AUTOSAR XML (schema 4-3-0)
package /ApplicationLayer/Interface
  impl type IntImpl: category=VALUE, base-type=uint8
  app type Int: category=VALUE
  impl type SwitchStatusImpl: category=VALUE, base-type=uint8
  app type SwitchStatus: category=VALUE
  impl type MotorInterfaceImpl: category=VALUE, base-type=uint8
  app type MotorInterface: category=VALUE
  data type mapping set TypeMappings
    data-type-maps:
      application-data-type=Int, implementation-data-type=IntImpl
      application-data-type=SwitchStatus, implementation-data-type=SwitchStatusImpl
      application-data-type=MotorInterface, implementation-data-type=MotorInterfaceImpl
  4 x sender receiver interface:
    DataInterface
      data message: type=Int
    swtInterface
      data status: type=SwitchStatus
    mInterface
      data status: type=MotorInterface
    sensorStatusInterface
      data value: type=Int
package /ApplicationLayer/ApplicationPackage
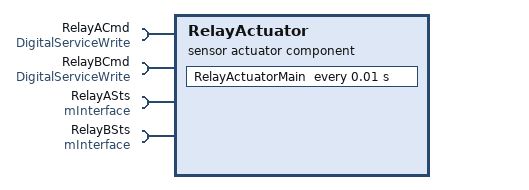
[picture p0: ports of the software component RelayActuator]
  sensor actuator sw component type RelayActuator
    4 x require port:
      RelayACmd: required-interface=DigitalServiceWrite
      RelayBCmd: required-interface=DigitalServiceWrite
      RelayASts: required-interface=mInterface
      RelayBSts: required-interface=mInterface
    behavior RelayActuatorBehavior: data-type-mapping=TypeMappings, handle-termination-and-restart=NO-SUPPORT
      timing event RelayActuatorMainEvent: start-on-event=RelayActuatorMain, period=0.01
      runnable RelayActuatorMain
        data-read-access:
          access dataReadAccess_RelayActuatorMain_RelayASts_status: accessed-variable=RelayASts.status
          access dataReadAccess_RelayActuatorMain_RelayBSts_status: accessed-variable=RelayBSts.status
        sync call RelayACmd_Write: operation=RelayACmd.Write, timeout=0.0
        sync call RelayBCmd_Write: operation=RelayBCmd.Write, timeout=0.0
  swc implementation RelayActuatorImpl: programming-language=C, vendor-id=0, behavior=RelayActuatorBehavior
    code-descriptors:
      code src: artifact-descriptors=autosar-engineering-object={short-label=artifactDescriptor, category=artifactDescriptorCategory}
    resource consumption resourceConsumption
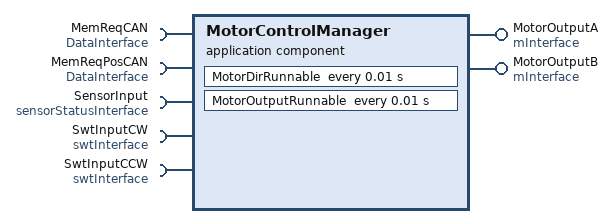
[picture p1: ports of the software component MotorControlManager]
  application sw component type MotorControlManager
    5 x require port:
      MemReqCAN: required-interface=DataInterface
      MemReqPosCAN: required-interface=DataInterface
      SensorInput: required-interface=sensorStatusInterface
      SwtInputCW: required-interface=swtInterface
      SwtInputCCW: required-interface=swtInterface
    provide port MotorOutputA: provided-interface=mInterface
    provide port MotorOutputB: provided-interface=mInterface
    behavior MotorControlManagerBehaviour: data-type-mapping=TypeMappings, handle-termination-and-restart=NO-SUPPORT
      timing event MotorDirRunnableEvent: start-on-event=MotorDirRunnable, period=0.01
      timing event MotorOutputRunnableEvent: start-on-event=MotorOutputRunnable, period=0.01
      runnable MotorDirRunnable: symbol=MotorDirRunnableMain
        data-read-access:
          5 x access:
            dataReadAccess_MotorDirRunnable_SwtInputCW_status: accessed-variable=SwtInputCW.status
            dataReadAccess_MotorDirRunnable_SwtInputCCW_status: accessed-variable=SwtInputCCW.status
            dataReadAccess_MotorDirRunnable_SensorInput_value: accessed-variable=SensorInput.value
            dataReadAccess_MotorDirRunnable_MemReqCAN_message: accessed-variable=MemReqCAN.message
            dataReadAccess_MotorDirRunnable_MemReqPosCAN_message: accessed-variable=MemReqPosCAN.message
      runnable MotorOutputRunnable: symbol=MotorOutputRunnableMain
        data-write-access:
          access dataWriteAccess_MotorOutputRunnable_MotorOutputA_status: accessed-variable=MotorOutputA.status
          access dataWriteAccess_MotorOutputRunnable_MotorOutputB_status: accessed-variable=MotorOutputB.status
  swc implementation MotorControlManagerImpl: programming-language=C, vendor-id=0, behavior=MotorControlManagerBehaviour
    code-descriptors:
      code src: artifact-descriptors=autosar-engineering-object={short-label=artifactDescriptor, category=artifactDescriptorCategory}
    resource consumption resourceConsumption
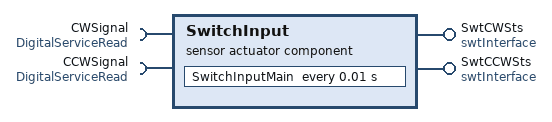
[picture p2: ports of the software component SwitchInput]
  sensor actuator sw component type SwitchInput
    require port CWSignal: required-interface=DigitalServiceRead
    require port CCWSignal: required-interface=DigitalServiceRead
    provide port SwtCWSts: provided-interface=swtInterface
    provide port SwtCCWSts: provided-interface=swtInterface
    behavior SwitchInputBehavior: data-type-mapping=TypeMappings, handle-termination-and-restart=NO-SUPPORT
      timing event SwitchInputMainEvent: start-on-event=SwitchInputMain, period=0.01
      runnable SwitchInputMain
        data-write-access:
          access dataWriteAccess_SwitchInputMain_SwtCWSts_status: accessed-variable=SwtCWSts.status
          access dataWriteAccess_SwitchInputMain_SwtCCWSts_status: accessed-variable=SwtCCWSts.status
        sync call CWSignal_Read: operation=CWSignal.Read, timeout=0.0
        sync call CCWSignal_Read: operation=CCWSignal.Read, timeout=0.0
  swc implementation SwitchInputImpl: programming-language=C, vendor-id=0, behavior=SwitchInputBehavior
    code-descriptors:
      code src: artifact-descriptors=autosar-engineering-object={short-label=artifactDescriptor, category=artifactDescriptorCategory}
    resource consumption resourceConsumption
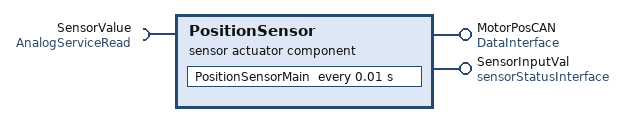
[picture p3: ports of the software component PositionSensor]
  sensor actuator sw component type PositionSensor
    require port SensorValue: required-interface=AnalogServiceRead
    provide port MotorPosCAN: provided-interface=DataInterface
    provide port SensorInputVal: provided-interface=sensorStatusInterface
    behavior PositionSensorBehavior: data-type-mapping=TypeMappings, handle-termination-and-restart=NO-SUPPORT
      timing event PositionSensorMainEvent: start-on-event=PositionSensorMain, period=0.01
      runnable PositionSensorMain
        data-write-access:
          access dataWriteAccess_PositionSensorMain_MotorPosCAN_message: accessed-variable=MotorPosCAN.message
          access dataWriteAccess_PositionSensorMain_SensorInputVal_value: accessed-variable=SensorInputVal.value
        sync call SensorValue_Read: operation=SensorValue.Read, timeout=0.0
  swc implementation PositionSensorImpl: programming-language=C, vendor-id=0, behavior=PositionSensorBehavior
    code-descriptors:
      code src: artifact-descriptors=autosar-engineering-object={short-label=artifactDescriptor, category=artifactDescriptorCategory}
    resource consumption resourceConsumption
package /ApplicationLayer/CompositionPackage
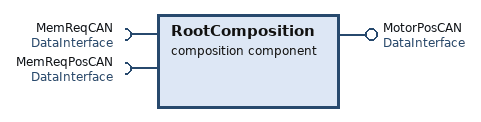
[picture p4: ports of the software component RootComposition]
  composition sw component type RootComposition
    require port MemReqCAN: required-interface=DataInterface
    require port MemReqPosCAN: required-interface=DataInterface
    provide port MotorPosCAN: provided-interface=DataInterface
    5 x component:
      PositionSensorInstance: type=PositionSensor
      SwitchInputInstance: type=SwitchInput
      RelayActuatorInstance: type=RelayActuator
      MotorControlManagerInstance: type=MotorControlManager
      IoHwAbInstance: type=IoHwAb
    connect SwitchInputInstance.SwtCWSts -> MotorControlManagerInstance.SwtInputCW
    connect SwitchInputInstance.SwtCCWSts -> MotorControlManagerInstance.SwtInputCCW
    connect MotorControlManagerInstance.MotorOutputA -> RelayActuatorInstance.RelayASts
    connect MotorControlManagerInstance.MotorOutputB -> RelayActuatorInstance.RelayBSts
    connect PositionSensorInstance.SensorInputVal -> MotorControlManagerInstance.SensorInput
    connect IoHwAbInstance.Digital_SwtCW -> SwitchInputInstance.CWSignal
    connect IoHwAbInstance.Digital_SwtCCW -> SwitchInputInstance.CCWSignal
    connect IoHwAbInstance.Digital_RelayA -> RelayActuatorInstance.RelayACmd
    connect IoHwAbInstance.Digital_RelayB -> RelayActuatorInstance.RelayBCmd
    connect IoHwAbInstance.Analog_Sensor -> PositionSensorInstance.SensorValue
    delegate MotorControlManagerInstance.MemReqCAN <-> outer port RootComposition/MemReqCAN
    delegate MotorControlManagerInstance.MemReqPosCAN <-> outer port RootComposition/MemReqPosCAN
    delegate PositionSensorInstance.MotorPosCAN <-> outer port RootComposition/MotorPosCAN
package /ApplicationLayer/Signals
  pdu ECU1_01_3FE: unused-bit-pattern=0
    signal ISignalSEAT_MEM_REQ_POS: 0 bit, data-type-policy=NETWORK-REPRESENTATION-FROM-COM-SPEC
    signal ISignalSEAT_MEM_Req: 0 bit, data-type-policy=NETWORK-REPRESENTATION-FROM-COM-SPEC
  pdu ECU2_01_3FF: unused-bit-pattern=0
    signal ISignalSEAT_POS: 0 bit, data-type-policy=NETWORK-REPRESENTATION-FROM-COM-SPEC
  pdu ECU01_01_3FE: unused-bit-pattern=0
    signal ISignalIntReq: 0 bit, data-type-policy=NETWORK-REPRESENTATION-FROM-COM-SPEC
  pdu MyECU_01_3FF: unused-bit-pattern=0
    signal ISignalLEDSts: 0 bit, data-type-policy=NETWORK-REPRESENTATION-FROM-COM-SPEC
    signal ISignalPotValue: 0 bit, data-type-policy=NETWORK-REPRESENTATION-FROM-COM-SPEC
package /ApplicationLayer/EcuExtract
  system MyAUTOSAREcuExtract: category=ECU_EXTRACT, system-version=1.0.0
    system mapping ImplementationMappings
      sw-impl-mappings:
        5 x swc to impl mapping:
          SwcToImplMapping_for_PositionSensorImpl_to_PositionSensorInstance: component-implementation=PositionSensorImpl, component=RootSwComposition.PositionSensorInstance
          SwcToImplMapping_for_SwitchInputImpl_to_SwitchInputInstance: component-implementation=SwitchInputImpl, component=RootSwComposition.SwitchInputInstance
          SwcToImplMapping_for_RelayActuatorImpl_to_RelayActuatorInstance: component-implementation=RelayActuatorImpl, component=RootSwComposition.RelayActuatorInstance
          SwcToImplMapping_for_MotorControlManagerImpl_to_MotorControlManagerInstance: component-implementation=MotorControlManagerImpl, component=RootSwComposition.MotorControlManagerInstance
          SwcToImplMapping_for_IoHwAbImpl_to_IoHwAbInstance: component-implementation=IoHwAbImpl, component=RootSwComposition.IoHwAbInstance
    system mapping SignalMappings
      data-mappings:
        data-element=RootSwComposition.MemReqCAN.message, system-signal=SEAT_MEM_Req
        data-element=RootSwComposition.MemReqPosCAN.message, system-signal=SEAT_MEM_REQ_POS
        data-element=RootSwComposition.MotorPosCAN.message, system-signal=SEAT_POS
    root-software-compositions:
      root sw composition prototype RootSwComposition: software-composition=RootComposition
package /BSWConfiguration/Services/IoHwAb
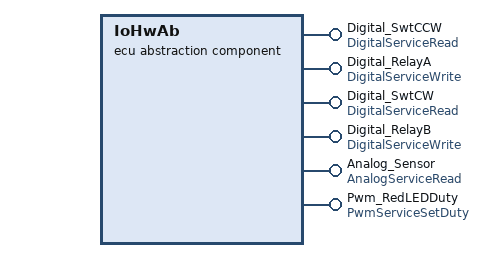
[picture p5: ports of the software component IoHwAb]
  ecu abstraction sw component type IoHwAb
    6 x provide port:
      Digital_SwtCCW: provided-interface=DigitalServiceRead
      Digital_RelayA: provided-interface=DigitalServiceWrite
      Digital_SwtCW: provided-interface=DigitalServiceRead
      Digital_RelayB: provided-interface=DigitalServiceWrite
      Analog_Sensor: provided-interface=AnalogServiceRead
      Pwm_RedLEDDuty: provided-interface=PwmServiceSetDuty
    behavior IoHwAbBehavior: handle-termination-and-restart=NO-SUPPORT
      6 x operation invoked event:
        DigitalRead_Digital_SwtCCW_Read: start-on-event=DigitalRead, operation=Digital_SwtCCW.Read
        DigitalRead_Digital_SwtCW_Read: start-on-event=DigitalRead, operation=Digital_SwtCW.Read
        DigitalWrite_Digital_RelayA_Write: start-on-event=DigitalWrite, operation=Digital_RelayA.Write
        DigitalWrite_Digital_RelayB_Write: start-on-event=DigitalWrite, operation=Digital_RelayB.Write
        AnalogRead_Analog_Sensor_Read: start-on-event=AnalogRead, operation=Analog_Sensor.Read
        PwmSetDuty_Pwm_RedLEDDuty_Set: start-on-event=PwmSetDuty, operation=Pwm_RedLEDDuty.Set
      port-api-options:
        {port-defined-argument-value{value=IoHwAb_SignalType_:0, value-type=IoHwAb_SignalType_}, port=Digital_SwtCCW}
        {port-defined-argument-value{value=IoHwAb_SignalType_:1, value-type=IoHwAb_SignalType_}, port=Digital_RelayA}
        {port-defined-argument-value{value=IoHwAb_SignalType_:2, value-type=IoHwAb_SignalType_}, port=Digital_SwtCW}
        {port-defined-argument-value{value=IoHwAb_SignalType_:3, value-type=IoHwAb_SignalType_}, port=Digital_RelayB}
        {port-defined-argument-value{value=IoHwAb_SignalType_:0, value-type=IoHwAb_SignalType_}, port=Analog_Sensor}
        {port-defined-argument-value{value=IoHwAb_SignalType_:0, value-type=IoHwAb_SignalType_}, port=Pwm_RedLEDDuty}
      4 x runnable, all with can-be-invoked-concurrently=true:
        DigitalRead: symbol=IoHwAb_Digital_Read
        DigitalWrite: symbol=IoHwAb_Digital_Write
        AnalogRead: symbol=IoHwAb_Analog_Read
        PwmSetDuty: symbol=IoHwAb_Pwm_Set_Duty
  swc implementation IoHwAbImpl: programming-language=C, vendor-id=60, behavior=IoHwAbBehavior
    code-descriptors:
      code src: artifact-descriptors=autosar-engineering-object={short-label=artifactDescriptor, category=artifactDescriptorCategory}
    resource consumption resourceConsumption
